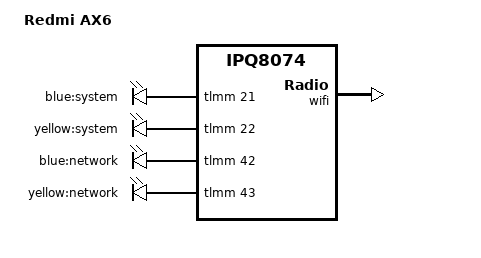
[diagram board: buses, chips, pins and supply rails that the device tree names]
// SPDX-License-Identifier: GPL-2.0-or-later OR MIT
/* Copyright (c) 2021, Zhijun You <hujy652@gmail.com> */

/dts-v1/;

#include "ipq8071-xiaomi.dtsi"

/ {
	model = "Redmi AX6";
	compatible = "redmi,ax6", "qcom,ipq8074";

	leds {
		compatible = "gpio-leds";

		led_system_blue: system-blue {
			label = "blue:system";
			gpios = <&tlmm 21 GPIO_ACTIVE_HIGH>;
		};

		led_system_yellow: system-yellow {
			label = "yellow:system";
			gpios = <&tlmm 22 GPIO_ACTIVE_HIGH>;
		};

		network-blue {
			label = "blue:network";
			gpios = <&tlmm 42 GPIO_ACTIVE_HIGH>;
		};

		network-yellow {
			label = "yellow:network";
			gpios = <&tlmm 43 GPIO_ACTIVE_HIGH>;
		};
	};
};

&q6_region {
	/* 512 MB board. The SoC default reserves 64 MB for a 1 GB layout.
	 * 55 MB is the size this board used before that default was applied.
	 * The following dump region starts at 0x4f000000, so only the length
	 * changes.
	 */
	reg = <0x0 0x4b000000 0x0 0x3700000>;
};

&edma {
	/* The default 2048-entry fill ring pins a page per descriptor on
	 * every queue. 512 covers a gigabit burst without pinning 8 MB per
	 * queue. 1 GB boards keep the driver default.
	 */
	rx-ring-size = <512>;
};

&wifi {
	status = "okay";
	qcom,calibration-variant = "Redmi-AX6";
};
